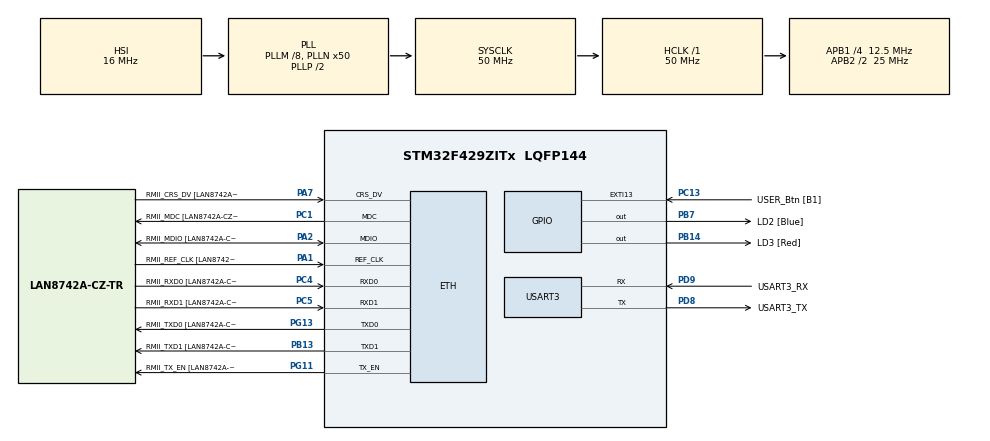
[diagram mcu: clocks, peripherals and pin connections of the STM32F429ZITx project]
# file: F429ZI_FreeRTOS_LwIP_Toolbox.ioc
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ETH.MediaInterface=ETH_MEDIA_INTERFACE_RMII
ETH.PHY_Name=LAN8742A_PHY_ADDRESS
ETH.PHY_Value=0
ETH.PhyAddress=0
FREERTOS.Queues01=user_queue1,16,uint16_t,0,Dynamic,NULL,NULL;user_queue2,16,uint16_t,0,Dynamic,NULL,NULL;user_queue3,16,uint16_t,0,Dynamic,NULL,NULL
FREERTOS.Tasks01=defaultTask,0,128,StartDefaultTask,Default,NULL,Dynamic,NULL,NULL;blinkTask,1,128,StartTask02,Default,NULL,Dynamic,NULL,NULL
LWIP.Version=v2.0.3_Cube
Mcu.Family=STM32F4
Mcu.Name=STM32F429ZITx
Mcu.Package=LQFP144
NVIC.ETH_IRQn=true\:5\:0\:false\:false\:true\:true\:true\:true
NVIC.EXTI15_10_IRQn=true\:5\:0\:false\:false\:true\:true\:true\:true
NVIC.PriorityGroup=NVIC_PRIORITYGROUP_4
NVIC.TIM2_IRQn=true\:0\:0\:false\:false\:true\:false\:false\:true
NVIC.TIM3_IRQn=true\:5\:0\:false\:false\:true\:true\:true\:true
NVIC.TIM4_IRQn=true\:5\:0\:false\:false\:true\:true\:true\:true
NVIC.TimeBase=TIM2_IRQn
NVIC.TimeBaseIP=TIM2
NVIC.USART3_IRQn=true\:5\:0\:false\:false\:true\:true\:true\:true
PA1.GPIO_Label=RMII_REF_CLK [LAN8742A-CZ-TR_REFCLK0]
PA1.Mode=RMII
PA1.Signal=ETH_REF_CLK
PA13.GPIO_Label=TMS
PA13.Mode=Serial_Wire
PA13.Signal=SYS_JTMS-SWDIO
PA14.GPIO_Label=TCK
PA14.Mode=Serial_Wire
PA14.Signal=SYS_JTCK-SWCLK
PA2.GPIO_Label=RMII_MDIO [LAN8742A-CZ-TR_MDIO]
PA2.Mode=RMII
PA2.Signal=ETH_MDIO
PA7.GPIO_Label=RMII_CRS_DV [LAN8742A-CZ-TR_CRS_DV]
PA7.Mode=RMII
PA7.Signal=ETH_CRS_DV
PB0.GPIO_Label=ETH_RXD2
PB0.Signal=ETH_RXD2
PB13.GPIO_Label=RMII_TXD1 [LAN8742A-CZ-TR_TXD1]
PB13.Mode=RMII
PB13.Signal=ETH_TXD1
PB14.GPIO_Label=LD3 [Red]
PB14.Signal=GPIO_Output
PB7.GPIO_Label=LD2 [Blue]
PB7.Signal=GPIO_Output
PC1.GPIO_Label=RMII_MDC [LAN8742A-CZ-TR_MDC]
PC1.Mode=RMII
PC1.Signal=ETH_MDC
PC13.GPIO_Label=USER_Btn [B1]
PC13.Signal=GPXTI13
PC4.GPIO_Label=RMII_RXD0 [LAN8742A-CZ-TR_RXD0]
PC4.Mode=RMII
PC4.Signal=ETH_RXD0
PC5.GPIO_Label=RMII_RXD1 [LAN8742A-CZ-TR_RXD1]
PC5.Mode=RMII
PC5.Signal=ETH_RXD1
PD8.GPIO_Label=USART3_TX
PD8.Mode=Asynchronous
PD8.Signal=USART3_TX
PD9.GPIO_Label=USART3_RX
PD9.Mode=Asynchronous
PD9.Signal=USART3_RX
PG11.GPIO_Label=RMII_TX_EN [LAN8742A-CZ-TR_TXEN]
PG11.Mode=RMII
PG11.Signal=ETH_TX_EN
PG13.GPIO_Label=RMII_TXD0 [LAN8742A-CZ-TR_TXD0]
PG13.Mode=RMII
PG13.Signal=ETH_TXD0
ProjectManager.HeapSize=0x200
ProjectManager.StackSize=0x400
ProjectManager.TargetToolchain=TrueSTUDIO
RCC.48MHZClocksFreq_Value=14285714.285714285
RCC.AHBFreq_Value=50000000
RCC.APB1CLKDivider=RCC_HCLK_DIV4
RCC.APB1Freq_Value=12500000
RCC.APB1TimFreq_Value=25000000
RCC.APB2CLKDivider=RCC_HCLK_DIV2
RCC.APB2Freq_Value=25000000
RCC.APB2TimCLKDivider=2
RCC.APB2TimFreq_Value=50000000
RCC.CortexFreq_Value=50000000
RCC.HCLKFreq_Value=50000000
RCC.HSE_VALUE=8000000
RCC.HSI_VALUE=16000000
RCC.LSE_VALUE=32768
RCC.PLLM=8
RCC.PLLMUL=RCC_PLL_MUL9
RCC.PLLN=50
RCC.PLLQ=7
RCC.PRESCALERUSB=RCC_USBCLKSOURCE_PLL_DIV1_5
RCC.SYSCLKFreq_VALUE=50000000
RCC.SYSCLKSource=RCC_SYSCLKSOURCE_PLLCLK
RCC.SYSCLKSourceVirtual=RCC_SYSCLKSOURCE_PLLCLK
RCC.USBFreq_Value=48000000
RCC.VCOOutputFreq_Value=100000000
USART3.VirtualMode=VM_ASYNC
VP_FREERTOS_VS_CMSIS_V1.Mode=CMSIS_V1
VP_LWIP_VS_Enabled.Mode=Enabled
VP_SYS_VS_tim2.Mode=TIM2
VP_TIM3_VS_ClockSourceINT.Mode=Internal
VP_TIM4_VS_ClockSourceINT.Mode=Internal
board=NUCLEO-F429ZI

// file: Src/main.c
/* USER CODE BEGIN Header */
/**
  ******************************************************************************
  * @file           : main.c
  * @brief          : Main program body
  ******************************************************************************
  * @attention
  *
  * <h2><center>&copy; Copyright (c) 2019 STMicroelectronics.
  * All rights reserved.</center></h2>
  *
  * This software component is licensed by ST under Ultimate Liberty license
  * SLA0044, the "License"; You may not use this file except in compliance with
  * the License. You may obtain a copy of the License at:
  *                             www.st.com/SLA0044
  *
  ******************************************************************************
  */
/* USER CODE END Header */

#include "main.h"
#include "cmsis_os.h"
#include "gfxsimulator.h"
#include "lwip.h"
#include "tim.h"
#include "usart.h"
#include "gpio.h"

void SystemClock_Config(void);
void MX_FREERTOS_Init(void);

int main(void)
{

  /* MCU Configuration--------------------------------------------------------*/

  /* Reset of all peripherals, Initializes the Flash interface and the Systick. */
  HAL_Init();

  /* Configure the system clock */
  SystemClock_Config();

  /* Initialize all configured peripherals */
  MX_GPIO_Init();
  // MX_GFXSIMULATOR_Init();
  MX_TIM3_Init();
  MX_TIM4_Init();
  MX_USART3_UART_Init();

  /* Call init function for freertos objects (in freertos.c) */
  MX_FREERTOS_Init();

  /* Start scheduler */
  osKernelStart();

  /* We should never get here as control is now taken by the scheduler */

  /* Infinite loop */
  while (1)
  {

  }
}

void SystemClock_Config(void)
{
  RCC_OscInitTypeDef RCC_OscInitStruct = {0};
  RCC_ClkInitTypeDef RCC_ClkInitStruct = {0};

  /** Configure the main internal regulator output voltage
  */
  __HAL_RCC_PWR_CLK_ENABLE();
  __HAL_PWR_VOLTAGESCALING_CONFIG(PWR_REGULATOR_VOLTAGE_SCALE3);
  /** Initializes the CPU, AHB and APB busses clocks
  */
  RCC_OscInitStruct.OscillatorType = RCC_OSCILLATORTYPE_HSI;
  RCC_OscInitStruct.HSIState = RCC_HSI_ON;
  RCC_OscInitStruct.HSICalibrationValue = RCC_HSICALIBRATION_DEFAULT;
  RCC_OscInitStruct.PLL.PLLState = RCC_PLL_ON;
  RCC_OscInitStruct.PLL.PLLSource = RCC_PLLSOURCE_HSI;
  RCC_OscInitStruct.PLL.PLLM = 8;
  RCC_OscInitStruct.PLL.PLLN = 50;
  RCC_OscInitStruct.PLL.PLLP = RCC_PLLP_DIV2;
  RCC_OscInitStruct.PLL.PLLQ = 7;
  if (HAL_RCC_OscConfig(&RCC_OscInitStruct) != HAL_OK)
  {
    Error_Handler();
  }
  /** Initializes the CPU, AHB and APB busses clocks
  */
  RCC_ClkInitStruct.ClockType = RCC_CLOCKTYPE_HCLK|RCC_CLOCKTYPE_SYSCLK
                              |RCC_CLOCKTYPE_PCLK1|RCC_CLOCKTYPE_PCLK2;
  RCC_ClkInitStruct.SYSCLKSource = RCC_SYSCLKSOURCE_PLLCLK;
  RCC_ClkInitStruct.AHBCLKDivider = RCC_SYSCLK_DIV1;
  RCC_ClkInitStruct.APB1CLKDivider = RCC_HCLK_DIV4;
  RCC_ClkInitStruct.APB2CLKDivider = RCC_HCLK_DIV2;

  if (HAL_RCC_ClockConfig(&RCC_ClkInitStruct, FLASH_LATENCY_1) != HAL_OK)
  {
    Error_Handler();
  }
}

void HAL_TIM_PeriodElapsedCallback(TIM_HandleTypeDef *htim)
{
  if (htim->Instance == TIM2) {
    HAL_IncTick();
  }
}

void Error_Handler(void)
{
}

/************************ (C) COPYRIGHT STMicroelectronics *****END OF FILE****/

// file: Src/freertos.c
/* USER CODE BEGIN Header */
/**
  ******************************************************************************
  * File Name          : freertos.c
  * Description        : Code for freertos applications
  ******************************************************************************
  * @attention
  *
  * <h2><center>&copy; Copyright (c) 2019 STMicroelectronics.
  * All rights reserved.</center></h2>
  *
  * This software component is licensed by ST under Ultimate Liberty license
  * SLA0044, the "License"; You may not use this file except in compliance with
  * the License. You may obtain a copy of the License at:
  *                             www.st.com/SLA0044
  *
  ******************************************************************************
  */
/* USER CODE END Header */

#include "FreeRTOS.h"
#include "task.h"
#include "main.h"
#include "cmsis_os.h"

osThreadId defaultTaskHandle;
osThreadId blinkTaskHandle;
osMessageQId user_queue1Handle;
osMessageQId user_queue2Handle;
osMessageQId user_queue3Handle;

void StartDefaultTask(void const * argument);
void StartTask02(void const * argument);

extern void MX_LWIP_Init(void);
void MX_FREERTOS_Init(void); /* (MISRA C 2004 rule 8.1) */

void MX_FREERTOS_Init(void) {

  /* Create the queue(s) */
  /* definition and creation of user_queue1 */
  osMessageQDef(user_queue1, 16, uint16_t);
  user_queue1Handle = osMessageCreate(osMessageQ(user_queue1), NULL);

  /* definition and creation of user_queue2 */
  osMessageQDef(user_queue2, 16, uint16_t);
  user_queue2Handle = osMessageCreate(osMessageQ(user_queue2), NULL);

  /* definition and creation of user_queue3 */
  osMessageQDef(user_queue3, 16, uint16_t);
  user_queue3Handle = osMessageCreate(osMessageQ(user_queue3), NULL);

  /* Create the thread(s) */
  /* definition and creation of defaultTask */
  osThreadDef(defaultTask, StartDefaultTask, osPriorityNormal, 0, 128);
  defaultTaskHandle = osThreadCreate(osThread(defaultTask), NULL);

  /* definition and creation of blinkTask */
  osThreadDef(blinkTask, StartTask02, osPriorityAboveNormal, 0, 128);
  blinkTaskHandle = osThreadCreate(osThread(blinkTask), NULL);

}

void StartDefaultTask(void const * argument)
{
  /* init code for LWIP */
  MX_LWIP_Init();

  /* USER CODE BEGIN StartDefaultTask */
  HAL_GPIO_WritePin(LD3_GPIO_Port, LD3_Pin, GPIO_PIN_SET);

  /* Infinite loop */
  for(;;)
  {
	    osDelay(1);
  }
  /* USER CODE END StartDefaultTask */
}

void StartTask02(void const * argument)
{
  /* USER CODE BEGIN StartTask02 */
  HAL_GPIO_WritePin(LD2_GPIO_Port, LD2_Pin, GPIO_PIN_SET);

  /* Infinite loop */
  for(;;)
  {
	  HAL_GPIO_TogglePin(LD2_GPIO_Port, LD2_Pin);
	  osDelay(500);
  }
  /* USER CODE END StartTask02 */
}

/************************ (C) COPYRIGHT STMicroelectronics *****END OF FILE****/
